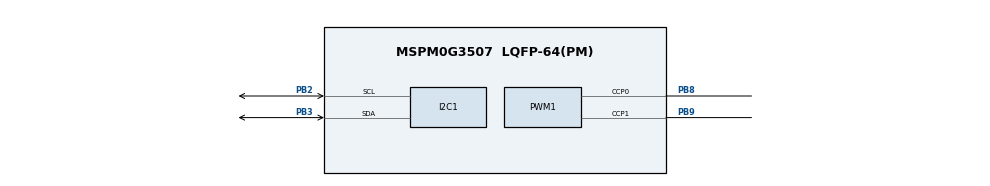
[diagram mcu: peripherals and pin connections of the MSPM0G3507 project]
/**
 * These arguments were used when this file was generated. They will be automatically applied on subsequent loads
 * via the GUI or CLI. Run CLI with '--help' for additional information on how to override these arguments.
 * @cliArgs --device "MSPM0G350X" --part "Default" --package "LQFP-64(PM)" --product "mspm0_sdk@2.05.00.05"
 * @v2CliArgs --device "MSPM0G3507" --package "LQFP-64(PM)" --product "mspm0_sdk@2.05.00.05"
 * @versions {"tool":"1.24.0+4110"}
 */

/**
 * Import the modules used in this configuration.
 */
const GPIO   = scripting.addModule("/ti/driverlib/GPIO", {}, false);
const GPIO1  = GPIO.addInstance();
const GPIO2  = GPIO.addInstance();
const GPIO3  = GPIO.addInstance();
const I2C    = scripting.addModule("/ti/driverlib/I2C", {}, false);
const I2C1   = I2C.addInstance();
const PWM    = scripting.addModule("/ti/driverlib/PWM", {}, false);
const PWM1   = PWM.addInstance();
const SYSCTL = scripting.addModule("/ti/driverlib/SYSCTL");
const TIMER  = scripting.addModule("/ti/driverlib/TIMER", {}, false);
const TIMER1 = TIMER.addInstance();

/**
 * Write custom configuration values to the imported modules.
 */
const divider7       = system.clockTree["PLL_PDIV"];
divider7.divideValue = 2;

const divider9       = system.clockTree["UDIV"];
divider9.divideValue = 2;

const multiplier2         = system.clockTree["PLL_QDIV"];
multiplier2.multiplyValue = 5;

const mux8       = system.clockTree["HSCLKMUX"];
mux8.inputSelect = "HSCLKMUX_SYSPLL2X";

GPIO1.$name                          = "GPIO_motor";
GPIO1.associatedPins.create(5);
GPIO1.associatedPins[0].$name        = "PIN_AIN1";
GPIO1.associatedPins[0].assignedPort = "PORTB";
GPIO1.associatedPins[0].assignedPin  = "6";
GPIO1.associatedPins[1].$name        = "PIN_AIN2";
GPIO1.associatedPins[1].assignedPort = "PORTB";
GPIO1.associatedPins[1].assignedPin  = "7";
GPIO1.associatedPins[2].$name        = "PIN_BIN1";
GPIO1.associatedPins[2].assignedPort = "PORTB";
GPIO1.associatedPins[2].assignedPin  = "15";
GPIO1.associatedPins[3].$name        = "PIN_BIN2";
GPIO1.associatedPins[3].assignedPort = "PORTB";
GPIO1.associatedPins[3].assignedPin  = "0";
GPIO1.associatedPins[4].$name        = "PIN_STBY";
GPIO1.associatedPins[4].assignedPort = "PORTB";
GPIO1.associatedPins[4].assignedPin  = "16";

const Board = scripting.addModule("/ti/driverlib/Board", {}, false);

GPIO2.$name                          = "GPIO_Encoder";
GPIO2.associatedPins.create(4);
GPIO2.associatedPins[0].$name        = "PIN_Left_E1A";
GPIO2.associatedPins[0].direction    = "INPUT";
GPIO2.associatedPins[0].assignedPort = "PORTA";
GPIO2.associatedPins[0].assignedPin  = "12";
GPIO2.associatedPins[0].interruptEn  = true;
GPIO2.associatedPins[0].polarity     = "FALL";
GPIO2.associatedPins[1].$name        = "PIN_Left_E1B";
GPIO2.associatedPins[1].direction    = "INPUT";
GPIO2.associatedPins[1].assignedPin  = "13";
GPIO2.associatedPins[1].assignedPort = "PORTA";
GPIO2.associatedPins[2].$name        = "PIN_Right_E2A";
GPIO2.associatedPins[2].direction    = "INPUT";
GPIO2.associatedPins[2].assignedPort = "PORTB";
GPIO2.associatedPins[2].assignedPin  = "12";
GPIO2.associatedPins[2].interruptEn  = true;
GPIO2.associatedPins[2].polarity     = "FALL";
GPIO2.associatedPins[3].$name        = "PIN_Right_E2B";
GPIO2.associatedPins[3].direction    = "INPUT";
GPIO2.associatedPins[3].assignedPort = "PORTB";
GPIO2.associatedPins[3].assignedPin  = "17";

GPIO3.$name                          = "GPIO_LED";
GPIO3.associatedPins[0].$name        = "PIN_LED";
GPIO3.associatedPins[0].initialValue = "SET";
GPIO3.associatedPins[0].assignedPort = "PORTA";
GPIO3.associatedPins[0].assignedPin  = "0";

I2C1.$name                             = "I2C_OLED";
I2C1.basicEnableController             = true;
I2C1.basicControllerStandardBusSpeed   = "Fast";
I2C1.peripheral.$assign                = "I2C1";
I2C1.peripheral.sdaPin.$assign         = "PB3";
I2C1.peripheral.sclPin.$assign         = "PB2";
I2C1.sdaPinConfig.$name                = "ti_driverlib_gpio_GPIOPinGeneric0";
I2C1.sdaPinConfig.hideOutputInversion  = scripting.forceWrite(false);
I2C1.sdaPinConfig.onlyInternalResistor = scripting.forceWrite(false);
I2C1.sdaPinConfig.passedPeripheralType = scripting.forceWrite("Digital");
I2C1.sclPinConfig.$name                = "ti_driverlib_gpio_GPIOPinGeneric1";
I2C1.sclPinConfig.hideOutputInversion  = scripting.forceWrite(false);
I2C1.sclPinConfig.onlyInternalResistor = scripting.forceWrite(false);
I2C1.sclPinConfig.passedPeripheralType = scripting.forceWrite("Digital");

PWM1.$name                      = "PWM_0";
PWM1.timerCount                 = 800;
PWM1.clockPrescale              = 100;
PWM1.peripheral.$assign         = "TIMA0";
PWM1.peripheral.ccp0Pin.$assign = "PB8";
PWM1.peripheral.ccp1Pin.$assign = "PB9";
PWM1.PWM_CHANNEL_0.$name        = "ti_driverlib_pwm_PWMTimerCC0";
PWM1.PWM_CHANNEL_1.$name        = "ti_driverlib_pwm_PWMTimerCC1";
PWM1.ccp0PinConfig.$name        = "ti_driverlib_gpio_GPIOPinGeneric2";
PWM1.ccp1PinConfig.$name        = "ti_driverlib_gpio_GPIOPinGeneric3";

SYSCTL.forceDefaultClkConfig = true;
SYSCTL.clockTreeEn           = true;
scripting.suppress("For best practices when the CPUCLK is running at 32MHz and above, clear the flash status bit using DL_FlashCTL_executeClearStatus\\(\\) before executing any flash operation\\. Otherwise there may be false positives\\.", SYSCTL);

TIMER1.$name              = "TIMER_speedget";
TIMER1.timerMode          = "PERIODIC";
TIMER1.timerPeriod        = "50 ms";
TIMER1.timerClkPrescale   = 100;
TIMER1.peripheral.$assign = "TIMG0";

/**
 * Pinmux solution for unlocked pins/peripherals. This ensures that minor changes to the automatic solver in a future
 * version of the tool will not impact the pinmux you originally saw.  These lines can be completely deleted in order to
 * re-solve from scratch.
 */
GPIO1.associatedPins[0].pin.$suggestSolution = "PB6";
GPIO1.associatedPins[1].pin.$suggestSolution = "PB7";
GPIO1.associatedPins[2].pin.$suggestSolution = "PB15";
GPIO1.associatedPins[3].pin.$suggestSolution = "PB0";
GPIO1.associatedPins[4].pin.$suggestSolution = "PB16";
Board.peripheral.$suggestSolution            = "DEBUGSS";
Board.peripheral.swclkPin.$suggestSolution   = "PA20";
Board.peripheral.swdioPin.$suggestSolution   = "PA19";
GPIO2.associatedPins[0].pin.$suggestSolution = "PA12";
GPIO2.associatedPins[1].pin.$suggestSolution = "PA13";
GPIO2.associatedPins[2].pin.$suggestSolution = "PB12";
GPIO2.associatedPins[3].pin.$suggestSolution = "PB17";
GPIO3.associatedPins[0].pin.$suggestSolution = "PA0";
